# RFC_PWR register map
Vendor: Texas Instruments
Peripheral module from a debugger description file (folder CC26x4).
Registers are 32-bit, access per field, reset 0x1 unless marked. A register's access mark holds for its fields unless they carry their own. Offsets are as the file gives them; lines under a group give offsets from that group; [hi:lo] are bit positions; {n}, {i} and the like mark numbered series; 'fields as' and 'values as' point back to an identical list; <NAME> marks a mode.

## RFC_PWR — RF core power management This module contains clock control for all RF core sub-modules.
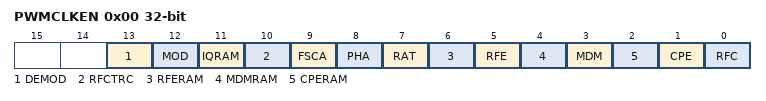
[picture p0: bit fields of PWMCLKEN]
0x00 PWMCLKEN — RF Core Power Management and Clock Enable
  [13] DEMOD rw — Enable clock to the Demodulator
  [12] MOD rw — Enable clock to the Modulator
  [11] IQRAM rw — Enable clock to IQ RAM in coherent demodulator
  [10] RFCTRC rw — Enable clock to the RF Core Tracer (RFCTRC) module.
  [9] FSCA rw — Enable clock to the Frequency Synthesizer Calibration Accelerator (FSCA) module.
  [8] PHA rw — Enable clock to the Packet Handling Accelerator (PHA) module.
  [7] RAT rw — Enable clock to the Radio Timer (RAT) module.
  [6] RFERAM rw — Enable clock to the RF Engine RAM module.
  [5] RFE rw — Enable clock to the RF Engine (RFE) module.
  [4] MDMRAM rw — Enable clock to the Modem RAM module.
  [3] MDM rw — Enable clock to the Modem (MDM) module.
  [2] CPERAM rw — Enable clock to the Command and Packet Engine (CPE) RAM module. As part of RF Core initialization, set this bit together with CPE bit to enable CPE to boot.
  [1] CPE rw — Enable processor clock (hclk) to the Command and Packet Engine (CPE). As part of RF Core initialization, set this bit together with CPERAM bit to enable CPE to boot.
  [0] RFC ro — Enable essential clocks for the RF Core interface. This includes the interconnect, the radio doorbell DBELL command interface, the power management (PWR) clock control module, and bus clock (sclk) for the CPE. To remove possibility of locking yourself out from the RF Core, this bit can not be cleared. If you need to disable all clocks to the RF Core, see the PRCM:RFCCLKG.CLK_EN register.
